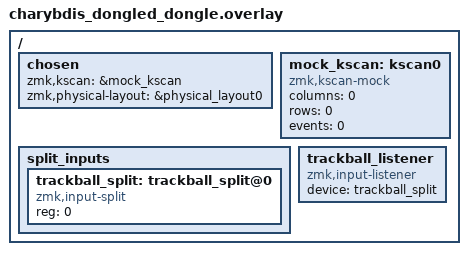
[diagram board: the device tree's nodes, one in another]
#include <dt-bindings/zmk/matrix_transform.h>
#include "charybdis_dongled-layout.dtsi"

/ {
    chosen {
        zmk,kscan = &mock_kscan;
        zmk,physical-layout = &physical_layout0;
    };

    // No real keys on the dongle
    mock_kscan: kscan0 {
        compatible = "zmk,kscan-mock";
        columns = <0>;
        rows = <0>;
        events = <0>;
    };

    split_inputs {
        #address-cells = <1>;
        #size-cells = <0>;

        trackball_split: trackball_split@0 {
            compatible = "zmk,input-split";
            reg = <0>;
        };
    };

    trackball_listener: trackball_listener {
        compatible = "zmk,input-listener";
        device = <&trackball_split>;
    };
};
